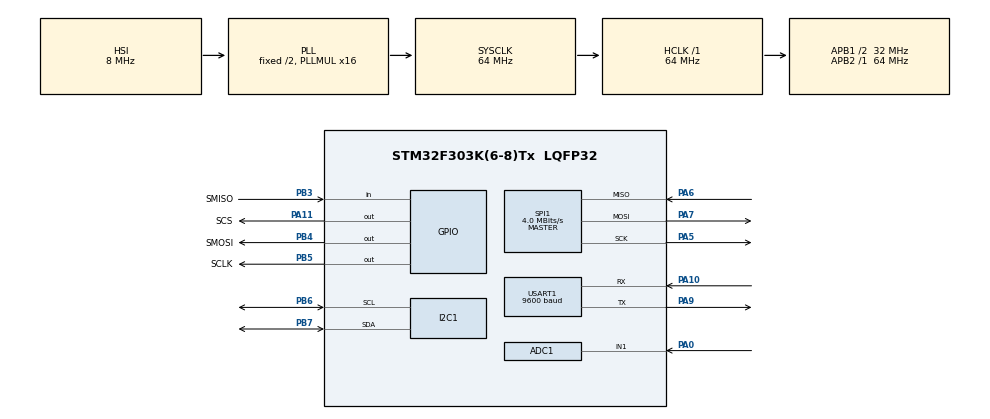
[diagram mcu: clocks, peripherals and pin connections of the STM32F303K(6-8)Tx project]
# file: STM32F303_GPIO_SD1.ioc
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ADC1.Channel-0\#ChannelRegularConversion=ADC_CHANNEL_1
ADC1.NbrOfConversionFlag=1
ADC1.Offset-0\#ChannelRegularConversion=0
ADC1.OffsetNumber-0\#ChannelRegularConversion=ADC_OFFSET_NONE
ADC1.Rank-0\#ChannelRegularConversion=1
ADC1.SamplingTime-0\#ChannelRegularConversion=ADC_SAMPLETIME_1CYCLE_5
ADC1.SubFamily=STM32F303x8
ADC1.master=1
Mcu.Family=STM32F3
Mcu.Name=STM32F303K(6-8)Tx
Mcu.Package=LQFP32
NVIC.PriorityGroup=NVIC_PRIORITYGROUP_4
PA0.Mode=IN1-Single-Ended
PA0.Signal=ADC1_IN1
PA10.Mode=Asynchronous
PA10.Signal=USART1_RX
PA11.GPIO_Label=SCS
PA11.GPIO_PuPd=GPIO_PULLUP
PA11.GPIO_Speed=GPIO_SPEED_FREQ_HIGH
PA11.Signal=GPIO_Output
PA13.GPIO_Label=SWDIO
PA13.Signal=SYS_JTMS-SWDIO
PA14.GPIO_Label=SWCLK
PA14.Signal=SYS_JTCK-SWCLK
PA15.GPIO_Label=VCP_RX
PA15.Signal=USART2_RX
PA2.GPIO_Label=VCP_TX
PA2.Signal=USART2_TX
PA5.Mode=Full_Duplex_Master
PA5.Signal=SPI1_SCK
PA6.Mode=Full_Duplex_Master
PA6.Signal=SPI1_MISO
PA7.Mode=Full_Duplex_Master
PA7.Signal=SPI1_MOSI
PA9.Mode=Asynchronous
PA9.Signal=USART1_TX
PB3.GPIO_Label=SMISO
PB3.GPIO_PuPd=GPIO_PULLUP
PB3.Signal=GPIO_Input
PB4.GPIO_Label=SMOSI
PB4.GPIO_PuPd=GPIO_PULLUP
PB4.GPIO_Speed=GPIO_SPEED_FREQ_HIGH
PB4.Signal=GPIO_Output
PB5.GPIO_Label=SCLK
PB5.GPIO_PuPd=GPIO_PULLUP
PB5.GPIO_Speed=GPIO_SPEED_FREQ_HIGH
PB5.Signal=GPIO_Output
PB6.Mode=I2C
PB6.Signal=I2C1_SCL
PB7.Mode=I2C
PB7.Signal=I2C1_SDA
PF0\ /\ OSC_IN.GPIO_Label=MCO
PF0\ /\ OSC_IN.Signal=RCC_OSC_IN
ProjectManager.HeapSize=0x200
ProjectManager.StackSize=0x400
ProjectManager.TargetToolchain=SW4STM32
RCC.AHBFreq_Value=64000000
RCC.APB1CLKDivider=RCC_HCLK_DIV2
RCC.APB1Freq_Value=32000000
RCC.APB1TimFreq_Value=64000000
RCC.APB2Freq_Value=64000000
RCC.APB2TimFreq_Value=64000000
RCC.CortexFreq_Value=64000000
RCC.HCLKFreq_Value=64000000
RCC.HSE_VALUE=8000000
RCC.HSI_VALUE=8000000
RCC.PLLMUL=RCC_PLL_MUL16
RCC.SYSCLKFreq_VALUE=64000000
RCC.SYSCLKSourceVirtual=RCC_SYSCLKSOURCE_PLLCLK
SPI1.BaudRatePrescaler=SPI_BAUDRATEPRESCALER_16
SPI1.CalculateBaudRate=4.0 MBits/s
SPI1.DataSize=SPI_DATASIZE_4BIT
SPI1.Mode=SPI_MODE_MASTER
USART1.BaudRate=9600
USART1.WordLength=UART_WORDLENGTH_8B
board=NUCLEO-F303K8

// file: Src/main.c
/**
  ******************************************************************************
  * File Name          : main.c
  * Description        : Main program body
  ******************************************************************************
  *
  * COPYRIGHT(c) 2016 STMicroelectronics
  *
  * Redistribution and use in source and binary forms, with or without modification,
  * are permitted provided that the following conditions are met:
  *   1. Redistributions of source code must retain the above copyright notice,
  *      this list of conditions and the following disclaimer.
  *   2. Redistributions in binary form must reproduce the above copyright notice,
  *      this list of conditions and the following disclaimer in the documentation
  *      and/or other materials provided with the distribution.
  *   3. Neither the name of STMicroelectronics nor the names of its contributors
  *      may be used to endorse or promote products derived from this software
  *      without specific prior written permission.
  *
  * THIS SOFTWARE IS PROVIDED BY THE COPYRIGHT HOLDERS AND CONTRIBUTORS "AS IS"
  * AND ANY EXPRESS OR IMPLIED WARRANTIES, INCLUDING, BUT NOT LIMITED TO, THE
  * IMPLIED WARRANTIES OF MERCHANTABILITY AND FITNESS FOR A PARTICULAR PURPOSE ARE
  * DISCLAIMED. IN NO EVENT SHALL THE COPYRIGHT HOLDER OR CONTRIBUTORS BE LIABLE
  * FOR ANY DIRECT, INDIRECT, INCIDENTAL, SPECIAL, EXEMPLARY, OR CONSEQUENTIAL
  * DAMAGES (INCLUDING, BUT NOT LIMITED TO, PROCUREMENT OF SUBSTITUTE GOODS OR
  * SERVICES; LOSS OF USE, DATA, OR PROFITS; OR BUSINESS INTERRUPTION) HOWEVER
  * CAUSED AND ON ANY THEORY OF LIABILITY, WHETHER IN CONTRACT, STRICT LIABILITY,
  * OR TORT (INCLUDING NEGLIGENCE OR OTHERWISE) ARISING IN ANY WAY OUT OF THE USE
  * OF THIS SOFTWARE, EVEN IF ADVISED OF THE POSSIBILITY OF SUCH DAMAGE.
  *
  ******************************************************************************
  */
#include "main.h"
#include "stm32f3xx_hal.h"
#include "ff.h"
/* USER CODE BEGIN Includes */
//#define _BV(bit) (1 << (bit))
/* USER CODE END Includes */

ADC_HandleTypeDef hadc1;

I2C_HandleTypeDef hi2c1;

SPI_HandleTypeDef hspi1;

UART_HandleTypeDef huart1;

/* USER CODE BEGIN PV */
/* Private variables ---------------------------------------------------------*/
int _write( int file, char *ptr, int len )
{
	HAL_UART_Transmit(&huart1, ptr, len, 1000);
  return len;

}
/* USER CODE END PV */

void SystemClock_Config(void);
void Error_Handler(void);
static void MX_GPIO_Init(void);
static void MX_ADC1_Init(void);
static void MX_I2C1_Init(void);
static void MX_SPI1_Init(void);
static void MX_USART1_UART_Init(void);

/* USER CODE BEGIN PFP */
/* Private function prototypes -----------------------------------------------*/

/* USER CODE END PFP */
FATFS FatFs;		/* FatFs work area needed for each volume */
FIL Fil;			/* File object needed for each open file */

int main(void)
{

  /* MCU Configuration----------------------------------------------------------*/

  /* Reset of all peripherals, Initializes the Flash interface and the Systick. */
  HAL_Init();

  /* Configure the system clock */
  SystemClock_Config();

  /* Initialize all configured peripherals */
  MX_GPIO_Init();
  MX_ADC1_Init();
  MX_I2C1_Init();
  MX_SPI1_Init();
  MX_USART1_UART_Init();

  /* USER CODE BEGIN 2 */
  printf("Initialize Success!!\n");
  /* USER CODE END 2 */

  /* Infinite loop */
  while (1)
  {
	  int bw;

	  if(f_mount(&FatFs, "", 1)==FR_OK)printf("Mount OK!! \n");
	  else {
		  printf("Mount Fail!! \n");
		  while(1){
//			  	HAL_GPIO_WritePin(GPIOA,GPIO_PIN_11,GPIO_PIN_SET);
//			  	HAL_GPIO_WritePin(GPIOA,GPIO_PIN_11,GPIO_PIN_RESET);
////			  	HAL_Delay(1);
//			  	GPIOA->BSRR = _BV(11);//GPIOA->BSRR= GPIO_PIN_11;
//				GPIOA->BSRR = _BV(11+16);//GPIOA->BRR= GPIO_PIN_11;

		  };
	  }
	  /* Give a work area to the default drive */
	  //HAL_Delay(10);
	  	if (f_open(&Fil, "newfile.txt", FA_WRITE | FA_CREATE_ALWAYS) == FR_OK) {	/* Create a file */

	  		f_write(&Fil, "It works!!!!!!!\r\n", 16, &bw);	/* Write data to the file */

	  		f_close(&Fil);								/* Close the file */

	  		if(bw==16)printf("Write OK!! \n");

	  		while(1);

	  	}else{

	  		printf("Open Fail!! \n");
	  		while(1);
	  	}

	  printf(" \n",(((GPIOB)->IDR & (GPIO_PIN_3)) == 0 ? 0 : 1));
	  HAL_Delay(300);
  }

}

/** System Clock Configuration
*/
void SystemClock_Config(void)
{

  RCC_OscInitTypeDef RCC_OscInitStruct;
  RCC_ClkInitTypeDef RCC_ClkInitStruct;
  RCC_PeriphCLKInitTypeDef PeriphClkInit;

    /**Initializes the CPU, AHB and APB busses clocks
    */
  RCC_OscInitStruct.OscillatorType = RCC_OSCILLATORTYPE_HSI;
  RCC_OscInitStruct.HSIState = RCC_HSI_ON;
  RCC_OscInitStruct.HSICalibrationValue = 16;
  RCC_OscInitStruct.PLL.PLLState = RCC_PLL_ON;
  RCC_OscInitStruct.PLL.PLLSource = RCC_PLLSOURCE_HSI;
  RCC_OscInitStruct.PLL.PLLMUL = RCC_PLL_MUL16;
  if (HAL_RCC_OscConfig(&RCC_OscInitStruct) != HAL_OK)
  {
    Error_Handler();
  }

    /**Initializes the CPU, AHB and APB busses clocks
    */
  RCC_ClkInitStruct.ClockType = RCC_CLOCKTYPE_HCLK|RCC_CLOCKTYPE_SYSCLK
                              |RCC_CLOCKTYPE_PCLK1|RCC_CLOCKTYPE_PCLK2;
  RCC_ClkInitStruct.SYSCLKSource = RCC_SYSCLKSOURCE_PLLCLK;
  RCC_ClkInitStruct.AHBCLKDivider = RCC_SYSCLK_DIV1;
  RCC_ClkInitStruct.APB1CLKDivider = RCC_HCLK_DIV2;
  RCC_ClkInitStruct.APB2CLKDivider = RCC_HCLK_DIV1;

  if (HAL_RCC_ClockConfig(&RCC_ClkInitStruct, FLASH_LATENCY_2) != HAL_OK)
  {
    Error_Handler();
  }

  PeriphClkInit.PeriphClockSelection = RCC_PERIPHCLK_USART1|RCC_PERIPHCLK_I2C1
                              |RCC_PERIPHCLK_ADC12;
  PeriphClkInit.Usart1ClockSelection = RCC_USART1CLKSOURCE_PCLK1;
  PeriphClkInit.Adc12ClockSelection = RCC_ADC12PLLCLK_DIV1;
  PeriphClkInit.I2c1ClockSelection = RCC_I2C1CLKSOURCE_HSI;
  if (HAL_RCCEx_PeriphCLKConfig(&PeriphClkInit) != HAL_OK)
  {
    Error_Handler();
  }

    /**Configure the Systick interrupt time
    */
  HAL_SYSTICK_Config(HAL_RCC_GetHCLKFreq()/1000);

    /**Configure the Systick
    */
  HAL_SYSTICK_CLKSourceConfig(SYSTICK_CLKSOURCE_HCLK);

  /* SysTick_IRQn interrupt configuration */
  HAL_NVIC_SetPriority(SysTick_IRQn, 0, 0);
}

/* ADC1 init function */
static void MX_ADC1_Init(void)
{

  ADC_ChannelConfTypeDef sConfig;

    /**Common config
    */
  hadc1.Instance = ADC1;
  hadc1.Init.ClockPrescaler = ADC_CLOCK_ASYNC_DIV1;
  hadc1.Init.Resolution = ADC_RESOLUTION_12B;
  hadc1.Init.ScanConvMode = ADC_SCAN_DISABLE;
  hadc1.Init.ContinuousConvMode = DISABLE;
  hadc1.Init.DiscontinuousConvMode = DISABLE;
  hadc1.Init.ExternalTrigConvEdge = ADC_EXTERNALTRIGCONVEDGE_NONE;
  hadc1.Init.DataAlign = ADC_DATAALIGN_RIGHT;
  hadc1.Init.NbrOfConversion = 1;
  hadc1.Init.DMAContinuousRequests = DISABLE;
  hadc1.Init.EOCSelection = ADC_EOC_SINGLE_CONV;
  hadc1.Init.LowPowerAutoWait = DISABLE;
  hadc1.Init.Overrun = ADC_OVR_DATA_OVERWRITTEN;
  if (HAL_ADC_Init(&hadc1) != HAL_OK)
  {
    Error_Handler();
  }

    /**Configure Regular Channel
    */
  sConfig.Channel = ADC_CHANNEL_1;
  sConfig.Rank = 1;
  sConfig.SingleDiff = ADC_SINGLE_ENDED;
  sConfig.SamplingTime = ADC_SAMPLETIME_1CYCLE_5;
  sConfig.OffsetNumber = ADC_OFFSET_NONE;
  sConfig.Offset = 0;
  if (HAL_ADC_ConfigChannel(&hadc1, &sConfig) != HAL_OK)
  {
    Error_Handler();
  }

}

/* I2C1 init function */
static void MX_I2C1_Init(void)
{

  hi2c1.Instance = I2C1;
  hi2c1.Init.Timing = 0x2000090E;
  hi2c1.Init.OwnAddress1 = 0;
  hi2c1.Init.AddressingMode = I2C_ADDRESSINGMODE_7BIT;
  hi2c1.Init.DualAddressMode = I2C_DUALADDRESS_DISABLE;
  hi2c1.Init.OwnAddress2 = 0;
  hi2c1.Init.OwnAddress2Masks = I2C_OA2_NOMASK;
  hi2c1.Init.GeneralCallMode = I2C_GENERALCALL_DISABLE;
  hi2c1.Init.NoStretchMode = I2C_NOSTRETCH_DISABLE;
  if (HAL_I2C_Init(&hi2c1) != HAL_OK)
  {
    Error_Handler();
  }

    /**Configure Analogue filter
    */
  if (HAL_I2CEx_ConfigAnalogFilter(&hi2c1, I2C_ANALOGFILTER_ENABLE) != HAL_OK)
  {
    Error_Handler();
  }

}

/* SPI1 init function */
static void MX_SPI1_Init(void)
{

  hspi1.Instance = SPI1;
  hspi1.Init.Mode = SPI_MODE_MASTER;
  hspi1.Init.Direction = SPI_DIRECTION_2LINES;
  hspi1.Init.DataSize = SPI_DATASIZE_4BIT;
  hspi1.Init.CLKPolarity = SPI_POLARITY_LOW;
  hspi1.Init.CLKPhase = SPI_PHASE_1EDGE;
  hspi1.Init.NSS = SPI_NSS_SOFT;
  hspi1.Init.BaudRatePrescaler = SPI_BAUDRATEPRESCALER_16;
  hspi1.Init.FirstBit = SPI_FIRSTBIT_MSB;
  hspi1.Init.TIMode = SPI_TIMODE_DISABLE;
  hspi1.Init.CRCCalculation = SPI_CRCCALCULATION_DISABLE;
  hspi1.Init.CRCPolynomial = 7;
  hspi1.Init.CRCLength = SPI_CRC_LENGTH_DATASIZE;
  hspi1.Init.NSSPMode = SPI_NSS_PULSE_ENABLE;
  if (HAL_SPI_Init(&hspi1) != HAL_OK)
  {
    Error_Handler();
  }

}

/* USART1 init function */
static void MX_USART1_UART_Init(void)
{

  huart1.Instance = USART1;
  huart1.Init.BaudRate = 9600;
  huart1.Init.WordLength = UART_WORDLENGTH_8B;
  huart1.Init.StopBits = UART_STOPBITS_1;
  huart1.Init.Parity = UART_PARITY_NONE;
  huart1.Init.Mode = UART_MODE_TX_RX;
  huart1.Init.HwFlowCtl = UART_HWCONTROL_NONE;
  huart1.Init.OverSampling = UART_OVERSAMPLING_16;
  huart1.Init.OneBitSampling = UART_ONE_BIT_SAMPLE_DISABLE;
  huart1.AdvancedInit.AdvFeatureInit = UART_ADVFEATURE_NO_INIT;
  if (HAL_UART_Init(&huart1) != HAL_OK)
  {
    Error_Handler();
  }

}

/** Configure pins as
        * Analog
        * Input
        * Output
        * EVENT_OUT
        * EXTI
     PA2   ------> USART2_TX
     PA15   ------> USART2_RX
*/
static void MX_GPIO_Init(void)
{

  GPIO_InitTypeDef GPIO_InitStruct;

  /* GPIO Ports Clock Enable */
  __HAL_RCC_GPIOF_CLK_ENABLE();
  __HAL_RCC_GPIOA_CLK_ENABLE();
  __HAL_RCC_GPIOB_CLK_ENABLE();

  /*Configure GPIO pins : VCP_TX_Pin VCP_RX_Pin */
  GPIO_InitStruct.Pin = VCP_TX_Pin|VCP_RX_Pin;
  GPIO_InitStruct.Mode = GPIO_MODE_AF_PP;
  GPIO_InitStruct.Pull = GPIO_NOPULL;
  GPIO_InitStruct.Speed = GPIO_SPEED_FREQ_HIGH;
  GPIO_InitStruct.Alternate = GPIO_AF7_USART2;
  HAL_GPIO_Init(GPIOA, &GPIO_InitStruct);

  /*Configure GPIO pin : SCS_Pin */
  GPIO_InitStruct.Pin = SCS_Pin;
  GPIO_InitStruct.Mode = GPIO_MODE_OUTPUT_PP;
  GPIO_InitStruct.Pull = GPIO_PULLUP;
  GPIO_InitStruct.Speed = GPIO_SPEED_FREQ_HIGH;//GPIO_SPEED_FREQ_LOW;//
  HAL_GPIO_Init(SCS_GPIO_Port, &GPIO_InitStruct);

  /*Configure GPIO pin : SMISO_Pin */
  GPIO_InitStruct.Pin = SMISO_Pin;
  GPIO_InitStruct.Mode = GPIO_MODE_INPUT;
  GPIO_InitStruct.Pull = GPIO_PULLUP;
  HAL_GPIO_Init(SMISO_GPIO_Port, &GPIO_InitStruct);

  /*Configure GPIO pins : SMOSI_Pin SCLK_Pin */
  GPIO_InitStruct.Pin = SMOSI_Pin|SCLK_Pin;
  GPIO_InitStruct.Mode = GPIO_MODE_OUTPUT_PP;
  GPIO_InitStruct.Pull = GPIO_PULLUP;
  GPIO_InitStruct.Speed = GPIO_SPEED_FREQ_HIGH;
  HAL_GPIO_Init(GPIOB, &GPIO_InitStruct);

  /*Configure GPIO pin Output Level */
  HAL_GPIO_WritePin(SCS_GPIO_Port, SCS_Pin, GPIO_PIN_SET);

  /*Configure GPIO pin Output Level */
  HAL_GPIO_WritePin(GPIOB, SMOSI_Pin|SCLK_Pin, GPIO_PIN_RESET);

}

void Error_Handler(void)
{
  while(1)
  {
  }
}

/************************ (C) COPYRIGHT STMicroelectronics *****END OF FILE****/
